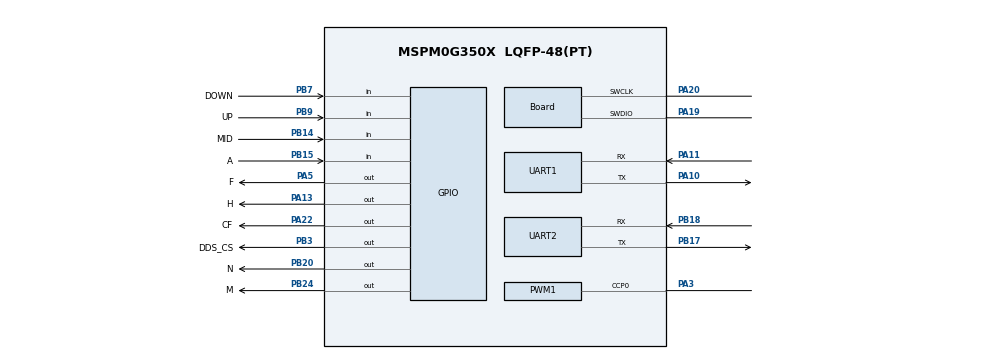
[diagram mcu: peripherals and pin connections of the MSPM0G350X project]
/**
 * @cliArgs --device "MSPM0G350X" --package "LQFP-48(PT)" --part "Default" --product "mspm0_sdk@2.01.00.03"
 * @versions {"tool":"1.19.0+3426"}
 */

/**
 * Import the modules used in this configuration.
 */
const ADC12         = scripting.addModule("/ti/driverlib/ADC12", {}, false);
const ADC121        = ADC12.addInstance();
const ADC122        = ADC12.addInstance();
const GPIO          = scripting.addModule("/ti/driverlib/GPIO", {}, false);
const GPIO1         = GPIO.addInstance();
const GPIO2         = GPIO.addInstance();
const GPIO3         = GPIO.addInstance();
const GPIO4         = GPIO.addInstance();
const GPIO5         = GPIO.addInstance();
const PWM           = scripting.addModule("/ti/driverlib/PWM", {}, false);
const PWM1          = PWM.addInstance();
const SYSCTL        = scripting.addModule("/ti/driverlib/SYSCTL");
const SYSTICK       = scripting.addModule("/ti/driverlib/SYSTICK");
const UART          = scripting.addModule("/ti/driverlib/UART", {}, false);
const UART1         = UART.addInstance();
const UART2         = UART.addInstance();
const ProjectConfig = scripting.addModule("/ti/project_config/ProjectConfig");

/**
 * Write custom configuration values to the imported modules.
 */
const divider9       = system.clockTree["UDIV"];
divider9.divideValue = 2;

const gate8  = system.clockTree["MFPCLKGATE"];
gate8.enable = true;

const multiplier2         = system.clockTree["PLL_QDIV"];
multiplier2.multiplyValue = 4;

const mux8       = system.clockTree["HSCLKMUX"];
mux8.inputSelect = "HSCLKMUX_SYSPLL0";

const mux12       = system.clockTree["SYSPLLMUX"];
mux12.inputSelect = "zSYSPLLMUX_HFCLK";

const pinFunction3     = system.clockTree["HFCLKEXT"];
pinFunction3.inputFreq = 40;
pinFunction3.enable    = true;

ADC121.$name                          = "ADC12_0";
ADC121.sampleTime0                    = "10 us";
ADC121.powerDownMode                  = "DL_ADC12_POWER_DOWN_MODE_MANUAL";
ADC121.adcMem1chansel                 = "DL_ADC12_INPUT_CHAN_1";
ADC121.sampClkSrc                     = "DL_ADC12_CLOCK_HFCLK";
ADC121.samplingOperationMode          = "sequence";
ADC121.startAdd                       = 6;
ADC121.endAdd                         = 9;
ADC121.adcMem7chansel                 = "DL_ADC12_INPUT_CHAN_1";
ADC121.adcMem8chansel                 = "DL_ADC12_INPUT_CHAN_2";
ADC121.adcMem9chansel                 = "DL_ADC12_INPUT_CHAN_3";
ADC121.enabledInterrupts              = ["DL_ADC12_INTERRUPT_MEM9_RESULT_LOADED"];
ADC121.adcPin0Config.$name            = "ti_driverlib_gpio_GPIOPinGeneric2";
ADC121.adcPin1Config.$name            = "ti_driverlib_gpio_GPIOPinGeneric13";
ADC121.adcPin2Config.$name            = "ti_driverlib_gpio_GPIOPinGeneric14";
ADC121.adcPin2Config.enableConfig     = true;
ADC121.adcPin2Config.internalResistor = "PULL_DOWN";
ADC121.adcPin3Config.$name            = "ti_driverlib_gpio_GPIOPinGeneric15";

ADC122.$name                          = "ADC12_1";
ADC122.adcMem2chansel                 = "DL_ADC12_INPUT_CHAN_2";
ADC122.adcMem1chansel                 = "DL_ADC12_INPUT_CHAN_1";
ADC122.powerDownMode                  = "DL_ADC12_POWER_DOWN_MODE_MANUAL";
ADC122.sampClkDiv                     = "DL_ADC12_CLOCK_DIVIDE_8";
ADC122.sampleTime0                    = "10us";
ADC122.samplingOperationMode          = "sequence";
ADC122.adcMem3chansel                 = "DL_ADC12_INPUT_CHAN_3";
ADC122.adcMem6chansel                 = "DL_ADC12_INPUT_CHAN_7";
ADC122.adcMem7chansel                 = "DL_ADC12_INPUT_CHAN_8";
ADC122.endAdd                         = 5;
ADC122.adcMem4chansel                 = "DL_ADC12_INPUT_CHAN_6";
ADC122.adcMem5chansel                 = "DL_ADC12_INPUT_CHAN_7";
ADC122.enabledInterrupts              = ["DL_ADC12_INTERRUPT_MEM5_RESULT_LOADED"];
ADC122.peripheral.adcPin1.$assign     = "PA16";
ADC122.peripheral.adcPin2.$assign     = "PA17";
ADC122.adcPin0Config.$name            = "ti_driverlib_gpio_GPIOPinGeneric7";
ADC122.adcPin1Config.$name            = "ti_driverlib_gpio_GPIOPinGeneric6";
ADC122.adcPin2Config.$name            = "ti_driverlib_gpio_GPIOPinGeneric8";
ADC122.adcPin3Config.$name            = "ti_driverlib_gpio_GPIOPinGeneric5";
ADC122.adcPin3Config.enableConfig     = true;
ADC122.adcPin3Config.internalResistor = "PULL_DOWN";
ADC122.adcPin6Config.$name            = "ti_driverlib_gpio_GPIOPinGeneric11";
ADC122.adcPin6Config.enableConfig     = true;
ADC122.adcPin6Config.internalResistor = "PULL_DOWN";
ADC122.adcPin7Config.$name            = "ti_driverlib_gpio_GPIOPinGeneric12";
ADC122.adcPin7Config.enableConfig     = true;
ADC122.adcPin7Config.internalResistor = "PULL_DOWN";

const Board                       = scripting.addModule("/ti/driverlib/Board", {}, false);
Board.peripheral.$assign          = "DEBUGSS";
Board.peripheral.swclkPin.$assign = "PA20";
Board.peripheral.swdioPin.$assign = "PA19";

GPIO1.$name                          = "GPIO_LED";
GPIO1.associatedPins.create(7);
GPIO1.associatedPins[0].assignedPort = "PORTA";
GPIO1.associatedPins[0].assignedPin  = "4";
GPIO1.associatedPins[0].$name        = "G";
GPIO1.associatedPins[1].assignedPort = "PORTA";
GPIO1.associatedPins[1].assignedPin  = "5";
GPIO1.associatedPins[1].$name        = "F";
GPIO1.associatedPins[1].pin.$assign  = "PA5";
GPIO1.associatedPins[2].$name        = "H";
GPIO1.associatedPins[2].assignedPort = "PORTA";
GPIO1.associatedPins[2].assignedPin  = "13";
GPIO1.associatedPins[2].pin.$assign  = "PA13";
GPIO1.associatedPins[3].$name        = "CF";
GPIO1.associatedPins[3].assignedPort = "PORTA";
GPIO1.associatedPins[3].pin.$assign  = "PA22";
GPIO1.associatedPins[4].$name        = "K";
GPIO1.associatedPins[4].assignedPort = "PORTA";
GPIO1.associatedPins[4].assignedPin  = "23";
GPIO1.associatedPins[5].assignedPort = "PORTA";
GPIO1.associatedPins[5].assignedPin  = "14";
GPIO1.associatedPins[5].$name        = "L";
GPIO1.associatedPins[6].assignedPort = "PORTA";
GPIO1.associatedPins[6].$name        = "A12";
GPIO1.associatedPins[6].assignedPin  = "12";

GPIO2.$name                              = "GPIO_BTN";
GPIO2.associatedPins.create(3);
GPIO2.associatedPins[0].$name            = "MID";
GPIO2.associatedPins[0].direction        = "INPUT";
GPIO2.associatedPins[0].internalResistor = "PULL_UP";
GPIO2.associatedPins[0].assignedPort     = "PORTB";
GPIO2.associatedPins[0].assignedPin      = "14";
GPIO2.associatedPins[0].pin.$assign      = "PB14";
GPIO2.associatedPins[1].$name            = "UP";
GPIO2.associatedPins[1].direction        = "INPUT";
GPIO2.associatedPins[1].assignedPort     = "PORTB";
GPIO2.associatedPins[1].assignedPin      = "9";
GPIO2.associatedPins[1].pin.$assign      = "PB9";
GPIO2.associatedPins[2].$name            = "DOWN";
GPIO2.associatedPins[2].direction        = "INPUT";
GPIO2.associatedPins[2].assignedPort     = "PORTB";
GPIO2.associatedPins[2].assignedPin      = "7";
GPIO2.associatedPins[2].pin.$assign      = "PB7";

GPIO3.$name                          = "GPIO_ENC";
GPIO3.associatedPins.create(2);
GPIO3.associatedPins[0].$name        = "A";
GPIO3.associatedPins[0].direction    = "INPUT";
GPIO3.associatedPins[0].assignedPort = "PORTB";
GPIO3.associatedPins[0].assignedPin  = "15";
GPIO3.associatedPins[0].interruptEn  = true;
GPIO3.associatedPins[0].polarity     = "RISE";
GPIO3.associatedPins[0].pin.$assign  = "PB15";
GPIO3.associatedPins[1].$name        = "B";
GPIO3.associatedPins[1].direction    = "INPUT";
GPIO3.associatedPins[1].assignedPort = "PORTB";
GPIO3.associatedPins[1].assignedPin  = "16";
GPIO3.associatedPins[1].polarity     = "RISE";

GPIO4.$name                          = "GPIO_DDS";
GPIO4.associatedPins.create(5);
GPIO4.associatedPins[0].$name        = "DDS_SCLK";
GPIO4.associatedPins[0].assignedPort = "PORTA";
GPIO4.associatedPins[0].assignedPin  = "8";
GPIO4.associatedPins[1].$name        = "DDS_SDIO0";
GPIO4.associatedPins[1].assignedPort = "PORTA";
GPIO4.associatedPins[1].assignedPin  = "9";
GPIO4.associatedPins[2].$name        = "DDS_CS";
GPIO4.associatedPins[2].assignedPort = "PORTB";
GPIO4.associatedPins[2].assignedPin  = "3";
GPIO4.associatedPins[2].pin.$assign  = "PB3";
GPIO4.associatedPins[3].$name        = "DDS_UPDATE";
GPIO4.associatedPins[3].assignedPort = "PORTB";
GPIO4.associatedPins[3].assignedPin  = "2";
GPIO4.associatedPins[4].$name        = "DDS_RST";
GPIO4.associatedPins[4].assignedPort = "PORTA";
GPIO4.associatedPins[4].assignedPin  = "7";

GPIO5.$name                          = "GPIO_GRP";
GPIO5.associatedPins.create(2);
GPIO5.associatedPins[0].$name        = "M";
GPIO5.associatedPins[0].assignedPort = "PORTB";
GPIO5.associatedPins[0].assignedPin  = "24";
GPIO5.associatedPins[0].pin.$assign  = "PB24";
GPIO5.associatedPins[1].$name        = "N";
GPIO5.associatedPins[1].assignedPort = "PORTB";
GPIO5.associatedPins[1].assignedPin  = "20";
GPIO5.associatedPins[1].pin.$assign  = "PB20";

PWM1.$name                      = "PWM_0";
PWM1.clockPrescale              = 256;
PWM1.ccIndex                    = [0];
PWM1.peripheral.$assign         = "TIMG7";
PWM1.peripheral.ccp0Pin.$assign = "PA3";
PWM1.PWM_CHANNEL_0.$name        = "ti_driverlib_pwm_PWMTimerCC0";
PWM1.PWM_CHANNEL_0.dutyCycle    = 50;
PWM1.ccp0PinConfig.$name        = "ti_driverlib_gpio_GPIOPinGeneric10";

SYSCTL.clockTreeEn = true;
SYSCTL.MFPCLKEn    = true;

SYSTICK.periodEnable    = true;
SYSTICK.period          = 80000;
SYSTICK.interruptEnable = true;
SYSTICK.systickEnable   = true;

UART1.$name                    = "UART_0";
UART1.enabledInterrupts        = ["RX"];
UART1.targetBaudRate           = 115200;
UART1.peripheral.rxPin.$assign = "PA11";
UART1.peripheral.txPin.$assign = "PA10";
UART1.txPinConfig.$name        = "ti_driverlib_gpio_GPIOPinGeneric0";
UART1.rxPinConfig.$name        = "ti_driverlib_gpio_GPIOPinGeneric1";

UART2.$name                            = "UART_2";
UART2.targetBaudRate                   = 115200;
UART2.enabledInterrupts                = ["RX"];
UART2.peripheral.$assign               = "UART2";
UART2.peripheral.rxPin.$assign         = "PB18";
UART2.peripheral.txPin.$assign         = "PB17";
UART2.txPinConfig.direction            = scripting.forceWrite("OUTPUT");
UART2.txPinConfig.hideOutputInversion  = scripting.forceWrite(false);
UART2.txPinConfig.onlyInternalResistor = scripting.forceWrite(false);
UART2.txPinConfig.passedPeripheralType = scripting.forceWrite("Digital");
UART2.txPinConfig.$name                = "ti_driverlib_gpio_GPIOPinGeneric3";
UART2.rxPinConfig.hideOutputInversion  = scripting.forceWrite(false);
UART2.rxPinConfig.onlyInternalResistor = scripting.forceWrite(false);
UART2.rxPinConfig.passedPeripheralType = scripting.forceWrite("Digital");
UART2.rxPinConfig.$name                = "ti_driverlib_gpio_GPIOPinGeneric4";

ProjectConfig.deviceSpin = "MSPM0G3507";
scripting.suppress("Migrating requires going through the Switch Board or Device menu in the Device View section\\.", ProjectConfig, "deviceSpin");

/**
 * Pinmux solution for unlocked pins/peripherals. This ensures that minor changes to the automatic solver in a future
 * version of the tool will not impact the pinmux you originally saw.  These lines can be completely deleted in order to
 * re-solve from scratch.
 */
pinFunction3.peripheral.$suggestSolution            = "SYSCTL";
pinFunction3.peripheral.hfclkInPin.$suggestSolution = "PA6";
ADC121.peripheral.$suggestSolution                  = "ADC0";
ADC121.peripheral.adcPin0.$suggestSolution          = "PA27";
ADC121.peripheral.adcPin1.$suggestSolution          = "PA26";
ADC121.peripheral.adcPin2.$suggestSolution          = "PA25";
ADC121.peripheral.adcPin3.$suggestSolution          = "PA24";
ADC122.peripheral.$suggestSolution                  = "ADC1";
ADC122.peripheral.adcPin0.$suggestSolution          = "PA15";
ADC122.peripheral.adcPin3.$suggestSolution          = "PA18";
ADC122.peripheral.adcPin6.$suggestSolution          = "PB19";
ADC122.peripheral.adcPin7.$suggestSolution          = "PA21";
GPIO1.associatedPins[0].pin.$suggestSolution        = "PA4";
GPIO1.associatedPins[4].pin.$suggestSolution        = "PA23";
GPIO1.associatedPins[5].pin.$suggestSolution        = "PA14";
GPIO1.associatedPins[6].pin.$suggestSolution        = "PA12";
GPIO3.associatedPins[1].pin.$suggestSolution        = "PB16";
GPIO4.associatedPins[0].pin.$suggestSolution        = "PA8";
GPIO4.associatedPins[1].pin.$suggestSolution        = "PA9";
GPIO4.associatedPins[3].pin.$suggestSolution        = "PB2";
GPIO4.associatedPins[4].pin.$suggestSolution        = "PA7";
UART1.peripheral.$suggestSolution                   = "UART0";
